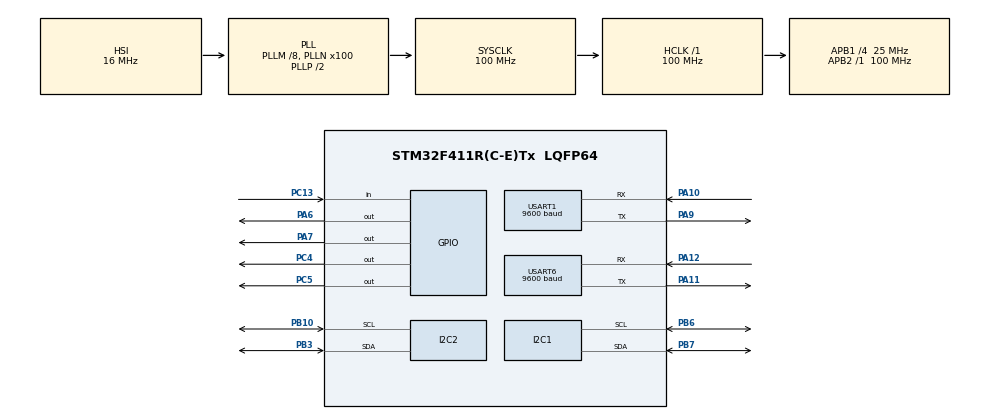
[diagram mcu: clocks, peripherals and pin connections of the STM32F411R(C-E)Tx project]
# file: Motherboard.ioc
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Mcu.Family=STM32F4
Mcu.Name=STM32F411R(C-E)Tx
Mcu.Package=LQFP64
NVIC.PriorityGroup=NVIC_PRIORITYGROUP_4
PA10.Mode=Asynchronous
PA10.Signal=USART1_RX
PA11.Mode=Asynchronous
PA11.Signal=USART6_TX
PA12.Mode=Asynchronous
PA12.Signal=USART6_RX
PA13.Mode=Serial_Wire
PA13.Signal=SYS_JTMS-SWDIO
PA14.Mode=Serial_Wire
PA14.Signal=SYS_JTCK-SWCLK
PA6.Signal=GPIO_Output
PA7.Signal=GPIO_Output
PA9.Mode=Asynchronous
PA9.Signal=USART1_TX
PB10.Mode=I2C
PB10.Signal=I2C2_SCL
PB3.Mode=I2C
PB3.Signal=I2C2_SDA
PB6.Mode=I2C
PB6.Signal=I2C1_SCL
PB7.Mode=I2C
PB7.Signal=I2C1_SDA
PC13-ANTI_TAMP.GPIO_PuPd=GPIO_PULLDOWN
PC13-ANTI_TAMP.Signal=GPIO_Input
PC14-OSC32_IN.Mode=LSE-External-Oscillator
PC14-OSC32_IN.Signal=RCC_OSC32_IN
PC15-OSC32_OUT.Mode=LSE-External-Oscillator
PC15-OSC32_OUT.Signal=RCC_OSC32_OUT
PC4.Signal=GPIO_Output
PC5.Signal=GPIO_Output
PH0\ -\ OSC_IN.Mode=HSE-External-Oscillator
PH0\ -\ OSC_IN.Signal=RCC_OSC_IN
PH1\ -\ OSC_OUT.Mode=HSE-External-Oscillator
PH1\ -\ OSC_OUT.Signal=RCC_OSC_OUT
ProjectManager.HeapSize=0x200
ProjectManager.StackSize=0x400
ProjectManager.TargetToolchain=SW4STM32
RCC.48MHZClocksFreq_Value=50000000
RCC.AHBFreq_Value=100000000
RCC.APB1CLKDivider=RCC_HCLK_DIV4
RCC.APB1Freq_Value=25000000
RCC.APB1TimFreq_Value=50000000
RCC.APB2Freq_Value=100000000
RCC.APB2TimFreq_Value=100000000
RCC.CortexFreq_Value=100000000
RCC.HCLKFreq_Value=100000000
RCC.HSE_VALUE=25000000
RCC.HSI_VALUE=16000000
RCC.PLLM=8
RCC.PLLN=100
RCC.SYSCLKFreq_VALUE=100000000
RCC.SYSCLKSource=RCC_SYSCLKSOURCE_PLLCLK
RCC.VCOOutputFreq_Value=200000000
USART1.BaudRate=9600
USART1.VirtualMode=VM_ASYNC
USART6.BaudRate=9600
USART6.VirtualMode=VM_ASYNC
board=Motherboard

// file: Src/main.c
/**
  ******************************************************************************
  * File Name          : main.c
  * Description        : Main program body
  ******************************************************************************
  *
  * COPYRIGHT(c) 2017 STMicroelectronics
  *
  * Redistribution and use in source and binary forms, with or without modification,
  * are permitted provided that the following conditions are met:
  *   1. Redistributions of source code must retain the above copyright notice,
  *      this list of conditions and the following disclaimer.
  *   2. Redistributions in binary form must reproduce the above copyright notice,
  *      this list of conditions and the following disclaimer in the documentation
  *      and/or other materials provided with the distribution.
  *   3. Neither the name of STMicroelectronics nor the names of its contributors
  *      may be used to endorse or promote products derived from this software
  *      without specific prior written permission.
  *
  * THIS SOFTWARE IS PROVIDED BY THE COPYRIGHT HOLDERS AND CONTRIBUTORS "AS IS"
  * AND ANY EXPRESS OR IMPLIED WARRANTIES, INCLUDING, BUT NOT LIMITED TO, THE
  * IMPLIED WARRANTIES OF MERCHANTABILITY AND FITNESS FOR A PARTICULAR PURPOSE ARE
  * DISCLAIMED. IN NO EVENT SHALL THE COPYRIGHT HOLDER OR CONTRIBUTORS BE LIABLE
  * FOR ANY DIRECT, INDIRECT, INCIDENTAL, SPECIAL, EXEMPLARY, OR CONSEQUENTIAL
  * DAMAGES (INCLUDING, BUT NOT LIMITED TO, PROCUREMENT OF SUBSTITUTE GOODS OR
  * SERVICES; LOSS OF USE, DATA, OR PROFITS; OR BUSINESS INTERRUPTION) HOWEVER
  * CAUSED AND ON ANY THEORY OF LIABILITY, WHETHER IN CONTRACT, STRICT LIABILITY,
  * OR TORT (INCLUDING NEGLIGENCE OR OTHERWISE) ARISING IN ANY WAY OUT OF THE USE
  * OF THIS SOFTWARE, EVEN IF ADVISED OF THE POSSIBILITY OF SUCH DAMAGE.
  *
  ******************************************************************************
  */
#include "main.h"
#include "stm32f4xx_hal.h"

I2C_HandleTypeDef hi2c1;
I2C_HandleTypeDef hi2c2;

UART_HandleTypeDef huart1;
UART_HandleTypeDef huart6;

/* USER CODE BEGIN PV */
/* Private variables ---------------------------------------------------------*/

/* USER CODE END PV */

void write_8bit_register(uint8_t register_pointer, uint16_t register_value);
void write_16bit_register(uint8_t register_pointer, uint16_t register_value);
void pca9685_init(I2C_HandleTypeDef *hi2c, uint8_t address);
void pca9685_pwm(I2C_HandleTypeDef *hi2c, uint8_t address, uint8_t num, uint16_t on, uint16_t off);
void SystemClock_Config(void);
void Error_Handler(void);
static void MX_GPIO_Init(void);
static void MX_I2C2_Init(void);
static void MX_USART6_UART_Init(void);
static void MX_USART1_UART_Init(void);
static void MX_I2C1_Init(void);

/* USER CODE BEGIN PFP */
/* Private function prototypes -----------------------------------------------*/

/* USER CODE END PFP */

int main(void)
{

  /* MCU Configuration----------------------------------------------------------*/

  /* Reset of all peripherals, Initializes the Flash interface and the Systick. */
  HAL_Init();

  /* Configure the system clock */
  SystemClock_Config();

  /* Initialize all configured peripherals */
  MX_GPIO_Init();
  MX_I2C2_Init();
  MX_USART6_UART_Init();
  MX_USART1_UART_Init();
  MX_I2C1_Init();

  /* USER CODE BEGIN 2 */
  uint8_t Test[] = "Hello World!";
  uint8_t Packet[17];
  uint8_t PWMPacket[50];
  PWMPacket[0] = 0x12;
  PWMPacket[1] = 0x21;
  PWMPacket[2] = 0x45;
  /* USER CODE END 2 */

  /* Infinite loop */
  /* USER CODE BEGIN WHILE */

  write_8bit_register(0x0, 0x0);	//reset PCA9685

  while (1)
  {
	  HAL_UART_Receive(&huart6,Packet,sizeof(Packet),10);
	  //HAL_Delay(20);
	  HAL_UART_Transmit(&huart6,Test,sizeof(Test), 10);
	  HAL_Delay(1);
//	  for(int i=0; i<3; i++){
//		 // HAL_I2C_Master_Transmit(&hi2c1,0x40<<1,PWMPacket[i],sizeof(PWMPacket[i]),10);
//		  HAL_I2C_Master_Transmit(&hi2c1, 0x80, &PWMPacket[i], 1, 1);
//		  //HAL_Delay(0.00001);
//	  }
	  //raw packet -> clean packet by verifying <[size of packet]> or some other checksum library
	  //HAL_GPIO_TogglePin(GPIOA, GPIO_PIN_6);
	  //HAL_Delay(1);
  /* USER CODE END WHILE */
	  pca9685_init(&hi2c1, 0x80);
	  write_8bit_register(0xFE, 0x03);		//set frequency of clock to 200HZ
//	  write_16bit_register(0x42, 500);
//	  write_16bit_register(0x44, 1000);
//	  HAL_Delay(50);
//  /* USER CODE BEGIN 3 */
	   pca9685_pwm(&hi2c1, 0x80, 15, 0, 1024);
	   HAL_Delay(5);

  }
  /* USER CODE END 3 */

}

//void PCA9685_setPrescale(uint8_t prescale){
//	uint8_t oldmode =
//}

void write_8bit_register(uint8_t register_pointer, uint16_t register_value){
    uint8_t data[3];

    data[0] = register_pointer;     // register address
    data[1] = register_value;       // byte of data

    HAL_I2C_Master_Transmit(&hi2c1, 0x40<<1, data, 2, 100);  // data is the start pointer of our array
}

void write_16bit_register(uint8_t register_pointer, uint16_t register_value){
    uint8_t data[3];

    data[0] = register_pointer;     // 0x0C in your example
    data[1] = register_value>>8;    // MSB byte of 16bit data
    data[2] = register_value;       // LSB byte of 16bit data

    HAL_I2C_Master_Transmit(&hi2c1, 0x40<<1, data, 3, 100);  // data is the start pointer of our array
}

void pca9685_init(I2C_HandleTypeDef *hi2c, uint8_t address){
 #define PCA9685_MODE1 0x00
 uint8_t initStruct[2];
 uint8_t prescale = 3; // hardcoded
 HAL_I2C_Master_Transmit(hi2c, address, 0x00, 1, 1);
 uint8_t oldmode = 0; // hardcoded
 // HAL_I2C_Master_Receive(hi2c, address, &oldmode, 1, 1);
 uint8_t newmode = ((oldmode & 0x7F) | 0x10);
 initStruct[0] = PCA9685_MODE1;
 initStruct[1] = newmode;
 HAL_I2C_Master_Transmit(hi2c, address, initStruct, 2, 1);
 initStruct[1] = prescale;
 HAL_I2C_Master_Transmit(hi2c, address, initStruct, 2, 1);
 initStruct[1] = oldmode;
 HAL_I2C_Master_Transmit(hi2c, address, initStruct, 2, 1);
 HAL_Delay(5);
 initStruct[1] = (oldmode | 0xA1);
 HAL_I2C_Master_Transmit(hi2c, address, initStruct, 2, 1);
}

void pca9685_pwm(I2C_HandleTypeDef *hi2c, uint8_t address, uint8_t num, uint16_t on, uint16_t off){
 uint8_t outputBuffer[5] = {0x06 + 4*num, on, (on >> 8), off, (off >> 8)};
 HAL_I2C_Master_Transmit(&hi2c1, address, outputBuffer, 5, 1);
}

/** System Clock Configuration
*/
void SystemClock_Config(void)
{

  RCC_OscInitTypeDef RCC_OscInitStruct;
  RCC_ClkInitTypeDef RCC_ClkInitStruct;

    /**Configure the main internal regulator output voltage
    */
  __HAL_RCC_PWR_CLK_ENABLE();

  __HAL_PWR_VOLTAGESCALING_CONFIG(PWR_REGULATOR_VOLTAGE_SCALE1);

    /**Initializes the CPU, AHB and APB busses clocks
    */
  RCC_OscInitStruct.OscillatorType = RCC_OSCILLATORTYPE_HSI;
  RCC_OscInitStruct.HSIState = RCC_HSI_ON;
  RCC_OscInitStruct.HSICalibrationValue = 16;
  RCC_OscInitStruct.PLL.PLLState = RCC_PLL_ON;
  RCC_OscInitStruct.PLL.PLLSource = RCC_PLLSOURCE_HSI;
  RCC_OscInitStruct.PLL.PLLM = 8;
  RCC_OscInitStruct.PLL.PLLN = 100;
  RCC_OscInitStruct.PLL.PLLP = RCC_PLLP_DIV2;
  RCC_OscInitStruct.PLL.PLLQ = 4;
  if (HAL_RCC_OscConfig(&RCC_OscInitStruct) != HAL_OK)
  {
    Error_Handler();
  }

    /**Initializes the CPU, AHB and APB busses clocks
    */
  RCC_ClkInitStruct.ClockType = RCC_CLOCKTYPE_HCLK|RCC_CLOCKTYPE_SYSCLK
                              |RCC_CLOCKTYPE_PCLK1|RCC_CLOCKTYPE_PCLK2;
  RCC_ClkInitStruct.SYSCLKSource = RCC_SYSCLKSOURCE_PLLCLK;
  RCC_ClkInitStruct.AHBCLKDivider = RCC_SYSCLK_DIV1;
  RCC_ClkInitStruct.APB1CLKDivider = RCC_HCLK_DIV4;
  RCC_ClkInitStruct.APB2CLKDivider = RCC_HCLK_DIV1;

  if (HAL_RCC_ClockConfig(&RCC_ClkInitStruct, FLASH_LATENCY_3) != HAL_OK)
  {
    Error_Handler();
  }

    /**Configure the Systick interrupt time
    */
  HAL_SYSTICK_Config(HAL_RCC_GetHCLKFreq()/1000);

    /**Configure the Systick
    */
  HAL_SYSTICK_CLKSourceConfig(SYSTICK_CLKSOURCE_HCLK);

  /* SysTick_IRQn interrupt configuration */
  HAL_NVIC_SetPriority(SysTick_IRQn, 0, 0);
}

/* I2C1 init function */
static void MX_I2C1_Init(void)
{

  hi2c1.Instance = I2C1;
  hi2c1.Init.ClockSpeed = 100000;
  hi2c1.Init.DutyCycle = I2C_DUTYCYCLE_2;
  hi2c1.Init.OwnAddress1 = 0;
  hi2c1.Init.AddressingMode = I2C_ADDRESSINGMODE_7BIT;
  hi2c1.Init.DualAddressMode = I2C_DUALADDRESS_DISABLE;
  hi2c1.Init.OwnAddress2 = 0;
  hi2c1.Init.GeneralCallMode = I2C_GENERALCALL_DISABLE;
  hi2c1.Init.NoStretchMode = I2C_NOSTRETCH_DISABLE;
  if (HAL_I2C_Init(&hi2c1) != HAL_OK)
  {
    Error_Handler();
  }

}

/* I2C2 init function */
static void MX_I2C2_Init(void)
{

  hi2c2.Instance = I2C2;
  hi2c2.Init.ClockSpeed = 100000;
  hi2c2.Init.DutyCycle = I2C_DUTYCYCLE_2;
  hi2c2.Init.OwnAddress1 = 0;
  hi2c2.Init.AddressingMode = I2C_ADDRESSINGMODE_7BIT;
  hi2c2.Init.DualAddressMode = I2C_DUALADDRESS_DISABLE;
  hi2c2.Init.OwnAddress2 = 0;
  hi2c2.Init.GeneralCallMode = I2C_GENERALCALL_DISABLE;
  hi2c2.Init.NoStretchMode = I2C_NOSTRETCH_DISABLE;
  if (HAL_I2C_Init(&hi2c2) != HAL_OK)
  {
    Error_Handler();
  }

}

/* USART1 init function */
static void MX_USART1_UART_Init(void)
{

  huart1.Instance = USART1;
  huart1.Init.BaudRate = 9600;
  huart1.Init.WordLength = UART_WORDLENGTH_8B;
  huart1.Init.StopBits = UART_STOPBITS_1;
  huart1.Init.Parity = UART_PARITY_NONE;
  huart1.Init.Mode = UART_MODE_TX_RX;
  huart1.Init.HwFlowCtl = UART_HWCONTROL_NONE;
  huart1.Init.OverSampling = UART_OVERSAMPLING_16;
  if (HAL_UART_Init(&huart1) != HAL_OK)
  {
    Error_Handler();
  }

}

/* USART6 init function */
static void MX_USART6_UART_Init(void)
{

  huart6.Instance = USART6;
  huart6.Init.BaudRate = 9600;
  huart6.Init.WordLength = UART_WORDLENGTH_8B;
  huart6.Init.StopBits = UART_STOPBITS_1;
  huart6.Init.Parity = UART_PARITY_NONE;
  huart6.Init.Mode = UART_MODE_TX_RX;
  huart6.Init.HwFlowCtl = UART_HWCONTROL_NONE;
  huart6.Init.OverSampling = UART_OVERSAMPLING_16;
  if (HAL_UART_Init(&huart6) != HAL_OK)
  {
    Error_Handler();
  }

}

/** Configure pins as
        * Analog
        * Input
        * Output
        * EVENT_OUT
        * EXTI
*/
static void MX_GPIO_Init(void)
{

  GPIO_InitTypeDef GPIO_InitStruct;

  /* GPIO Ports Clock Enable */
  __HAL_RCC_GPIOC_CLK_ENABLE();
  __HAL_RCC_GPIOH_CLK_ENABLE();
  __HAL_RCC_GPIOA_CLK_ENABLE();
  __HAL_RCC_GPIOB_CLK_ENABLE();

  /*Configure GPIO pin Output Level */
  HAL_GPIO_WritePin(GPIOA, GPIO_PIN_6|GPIO_PIN_7, GPIO_PIN_RESET);

  /*Configure GPIO pin Output Level */
  HAL_GPIO_WritePin(GPIOC, GPIO_PIN_4|GPIO_PIN_5, GPIO_PIN_RESET);

  /*Configure GPIO pin : PC13 */
  GPIO_InitStruct.Pin = GPIO_PIN_13;
  GPIO_InitStruct.Mode = GPIO_MODE_INPUT;
  GPIO_InitStruct.Pull = GPIO_PULLDOWN;
  HAL_GPIO_Init(GPIOC, &GPIO_InitStruct);

  /*Configure GPIO pins : PA6 PA7 */
  GPIO_InitStruct.Pin = GPIO_PIN_6|GPIO_PIN_7;
  GPIO_InitStruct.Mode = GPIO_MODE_OUTPUT_PP;
  GPIO_InitStruct.Pull = GPIO_NOPULL;
  GPIO_InitStruct.Speed = GPIO_SPEED_FREQ_LOW;
  HAL_GPIO_Init(GPIOA, &GPIO_InitStruct);

  /*Configure GPIO pins : PC4 PC5 */
  GPIO_InitStruct.Pin = GPIO_PIN_4|GPIO_PIN_5;
  GPIO_InitStruct.Mode = GPIO_MODE_OUTPUT_PP;
  GPIO_InitStruct.Pull = GPIO_NOPULL;
  GPIO_InitStruct.Speed = GPIO_SPEED_FREQ_LOW;
  HAL_GPIO_Init(GPIOC, &GPIO_InitStruct);

}

void Error_Handler(void)
{
  while(1)
  {
  }
}

/************************ (C) COPYRIGHT STMicroelectronics *****END OF FILE****/
